VERSION ""

NS_ :

BS_:

BU_: VDM CMR_DSMC SOBDMC_HPCM_FD1 IPMA_ADAS PSCM ABS_ESC TCCM TCM_DSL PCM_HEV PCM ECM_Diesel GWM

BO_ 390 ACCDATA: 8 IPMA_ADAS
 SG_ AccBrkPulse_B_Rq : 36|1@0+ (1,0) [0|1] "SED"  ABS_ESC,GWM
 SG_ AccAutoResum_D_Rq : 7|2@0+ (1,0) [0|3] "SED"  PCM_HEV,PCM,ECM_Diesel
 SG_ AccBrkTot_A_Rq : 4|13@0+ (0.0039,-20) [-20|11.9449] "m/s^2"  GWM,ABS_ESC
 SG_ AccPrpl_A_Pred : 17|10@0+ (0.01,-5) [-5|5.23] "m/s^2"  GWM,ECM_Diesel,PCM,PCM_HEV
 SG_ AccVeh_V_Trg : 32|9@0+ (0.5,0) [0|255.5] "kph"  GWM,ECM_Diesel,PCM,PCM_HEV,TCM_DSL
 SG_ AccBrkPrkEl_B_Rq : 38|1@0+ (1,0) [0|1] "SED"  GWM,ABS_ESC
 SG_ Cmbb_B_Enbl : 50|1@0+ (1,0) [0|1] "SED"  GWM
 SG_ CmbbOvrrd_B_RqDrv : 51|1@0+ (1,0) [0|1] "SED"  GWM
 SG_ CmbbDeny_B_Actl : 37|1@0+ (1,0) [0|1] "SED"  GWM,ABS_ESC
 SG_ CmbbEngTqMn_B_Rq : 52|1@0+ (1,0) [0|1] "SED"  ECM_Diesel,PCM,PCM_HEV,GWM
 SG_ AccPrpl_A_Rq : 49|10@0+ (0.01,-5) [-5|5.23] "m/s^2"  GWM,ECM_Diesel,PCM,PCM_HEV
 SG_ AccDeny_B_Rq : 53|1@0+ (1,0) [0|1] "SED"  GWM,ECM_Diesel,PCM,PCM_HEV
 SG_ AccResumEnbl_B_Rq : 33|1@0+ (1,0) [0|1] "SED"  GWM,ECM_Diesel,PCM,PCM_HEV
 SG_ AccCancl_B_Rq : 39|1@0+ (1,0) [0|1] "SED"  GWM,ABS_ESC,ECM_Diesel,PCM,PCM_HEV
 SG_ AccBrkPrchg_B_Rq : 54|1@0+ (1,0) [0|1] "SED"  GWM,ABS_ESC
 SG_ AccBrkDecel_B_Rq : 55|1@0+ (1,0) [0|1] "SED"  GWM,ABS_ESC
 SG_ AccStopStat_B_Rq : 34|1@0+ (1,0) [0|1] "SED"  GWM,ECM_Diesel,PCM,PCM_HEV,ABS_ESC

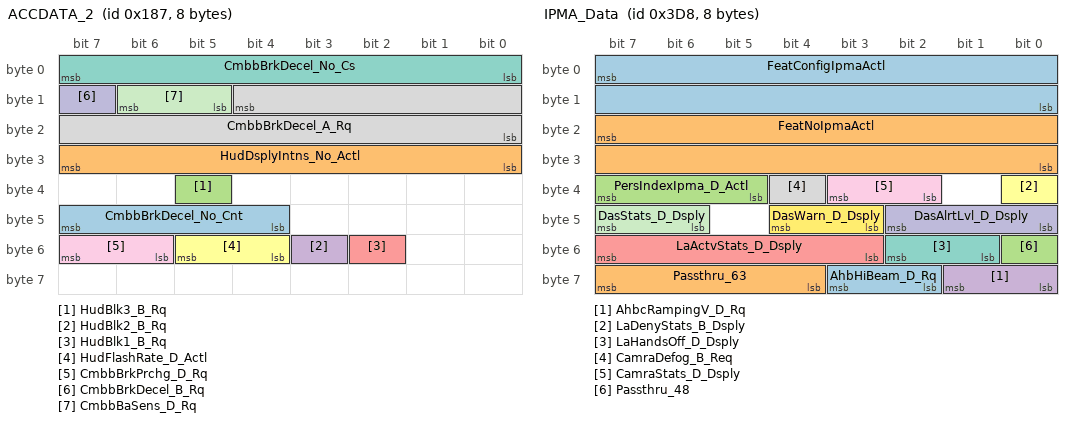
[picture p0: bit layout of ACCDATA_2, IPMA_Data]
BO_ 391 ACCDATA_2: 8 IPMA_ADAS
 SG_ CmbbBrkDecel_No_Cnt : 47|4@0+ (1,0) [0|15] "Unitless"  GWM,ABS_ESC
 SG_ HudDsplyIntns_No_Actl : 31|8@0+ (0.5,0) [0|100] "%"  GWM
 SG_ HudBlk3_B_Rq : 37|1@0+ (1,0) [0|1] "SED"  GWM
 SG_ HudBlk2_B_Rq : 51|1@0+ (1,0) [0|1] "SED"  GWM
 SG_ HudBlk1_B_Rq : 50|1@0+ (1,0) [0|1] "SED"  GWM
 SG_ HudFlashRate_D_Actl : 53|2@0+ (1,0) [0|3] "SED"  GWM
 SG_ CmbbBrkDecel_No_Cs : 7|8@0+ (1,0) [0|255] "Unitless"  GWM,ABS_ESC
 SG_ CmbbBrkDecel_A_Rq : 12|13@0+ (0.0039,-20) [-20|11.9449] "m/s^2"  ABS_ESC,GWM
 SG_ CmbbBrkPrchg_D_Rq : 55|2@0+ (1,0) [0|3] "SED"  ABS_ESC,GWM
 SG_ CmbbBrkDecel_B_Rq : 15|1@0+ (1,0) [0|1] "SED"  ABS_ESC,GWM
 SG_ CmbbBaSens_D_Rq : 14|2@0+ (1,0) [0|3] "SED"  ABS_ESC,GWM

BO_ 394 ACCDATA_3: 8 IPMA_ADAS
 SG_ HaDsply_No_Cs : 63|8@0+ (1,0) [0|255] "Unitless"  GWM
 SG_ HaDsply_No_Cnt : 4|4@0+ (1,0) [0|15] "Unitless"  GWM
 SG_ AccStopStat_D_Dsply : 41|2@0+ (1,0) [0|3] "SED"  GWM
 SG_ AccTrgDist2_D_Dsply : 27|4@0+ (1,0) [0|15] "SED"  GWM
 SG_ AccStopRes_B_Dsply : 54|1@0+ (1,0) [0|1] "SED"  GWM
 SG_ TjaWarn_D_Rq : 50|3@0+ (1,0) [0|7] "SED"  GWM
 SG_ Tja_D_Stat : 44|3@0+ (1,0) [0|7] "SED"  GWM
 SG_ TjaMsgTxt_D_Dsply : 53|3@0+ (1,0) [0|7] "SED"  GWM
 SG_ IaccLamp_D_Rq : 46|2@0+ (1,0) [0|3] "SED"  GWM
 SG_ AccMsgTxt_D2_Rq : 31|4@0+ (1,0) [0|15] "SED"  GWM
 SG_ FcwDeny_B_Dsply : 10|1@0+ (1,0) [0|1] "SED"  GWM
 SG_ FcwMemStat_B_Actl : 13|1@0+ (1,0) [0|1] "SED"  GWM
 SG_ AccTGap_B_Dsply : 35|1@0+ (1,0) [0|1] "SED"  GWM
 SG_ CadsAlignIncplt_B_Actl : 11|1@0+ (1,0) [0|1] "SED"  GWM
 SG_ AccFllwMde_B_Dsply : 17|1@0+ (1,0) [0|1] "SED"  GWM
 SG_ CadsRadrBlck_B_Actl : 22|1@0+ (1,0) [0|1] "SED"  GWM
 SG_ CmbbPostEvnt_B_Dsply : 15|1@0+ (1,0) [0|1] "SED"  GWM
 SG_ AccStopMde_B_Dsply : 0|1@0+ (1,0) [0|1] "SED"  GWM
 SG_ FcwMemSens_D_Actl : 20|2@0+ (1,0) [0|3] "SED"  GWM
 SG_ FcwMsgTxt_D_Rq : 7|3@0+ (1,0) [0|7] "SED"  GWM
 SG_ AccWarn_D_Dsply : 39|2@0+ (1,0) [0|3] "SED"  GWM
 SG_ FcwVisblWarn_B_Rq : 47|1@0+ (1,0) [0|1] "SED"  GWM
 SG_ FcwAudioWarn_B_Rq : 8|1@0+ (1,0) [0|1] "SED"  GWM
 SG_ AccTGap_D_Dsply : 34|3@0+ (1,0) [0|7] "SED"  GWM
 SG_ AccMemEnbl_B_RqDrv : 36|1@0+ (1,0) [0|1] "SED"  GWM
 SG_ FdaMem_B_Stat : 37|1@0+ (1,0) [0|1] "SED"  GWM

BO_ 984 IPMA_Data: 8 IPMA_ADAS
 SG_ FeatConfigIpmaActl : 7|16@0+ (1,0) [0|65535] "Undefined" GWM
 SG_ FeatNoIpmaActl : 23|16@0+ (1,0) [0|65535] "Number" GWM
 SG_ PersIndexIpma_D_Actl : 39|3@0+ (1,0) [0|7] "SED" GWM
 SG_ AhbcRampingV_D_Rq : 57|2@0+ (1,0) [0|3] "SED" GWM
 SG_ LaActvStats_D_Dsply : 55|5@0+ (1,0) [0|31] "SED" GWM
 SG_ LaDenyStats_B_Dsply : 32|1@0+ (1,0) [0|1] "SED" GWM
 SG_ LaHandsOff_D_Dsply : 50|2@0+ (1,0) [0|3] "SED" GWM
 SG_ CamraDefog_B_Req : 36|1@0+ (1,0) [0|1] "SED" GWM
 SG_ CamraStats_D_Dsply : 35|2@0+ (1,0) [0|3] "SED" GWM
 SG_ DasAlrtLvl_D_Dsply : 42|3@0+ (1,0) [0|7] "SED" GWM
 SG_ DasStats_D_Dsply : 47|2@0+ (1,0) [0|3] "SED" GWM
 SG_ DasWarn_D_Dsply : 44|2@0+ (1,0) [0|3] "SED" GWM
 SG_ AhbHiBeam_D_Rq : 59|2@0+ (1,0) [0|3] "SED" GWM
 SG_ Passthru_63 : 63|4@0+ (1,0) [0|15] "" XXX
 SG_ Passthru_48 : 48|1@0+ (1,0) [0|1] "" XXX

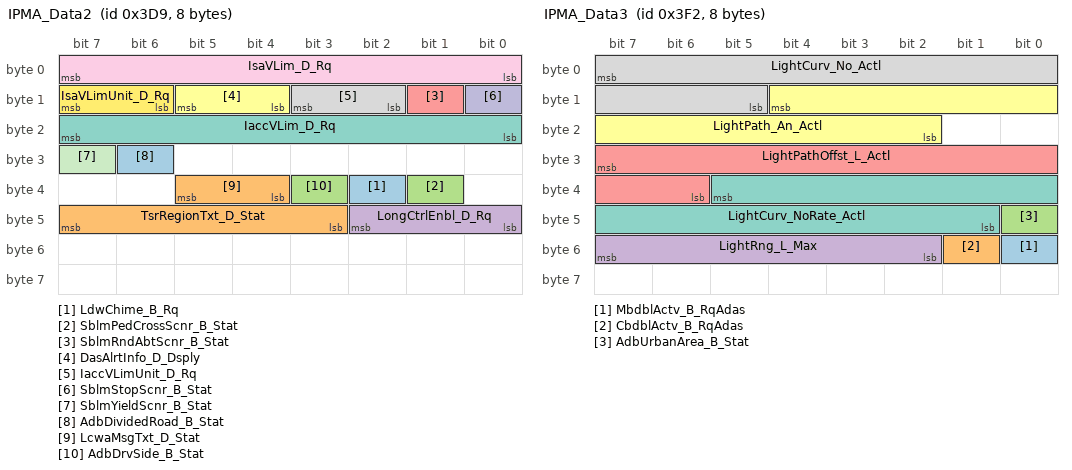
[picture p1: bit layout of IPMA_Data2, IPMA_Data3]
BO_ 985 IPMA_Data2: 8 IPMA_ADAS
 SG_ LdwChime_B_Rq : 34|1@0+ (1,0) [0|1] "SED" GWM
 SG_ TsrRegionTxt_D_Stat : 47|5@0+ (1,0) [0|31] "SED" GWM
 SG_ SblmPedCrossScnr_B_Stat : 33|1@0+ (1,0) [0|1] "SED" GWM
 SG_ LongCtrlEnbl_D_Rq : 42|3@0+ (1,0) [0|7] "SED" ECM_Diesel,PCM,PCM_HEV,GWM
 SG_ SblmRndAbtScnr_B_Stat : 9|1@0+ (1,0) [0|1] "SED" GWM
 SG_ DasAlrtInfo_D_Dsply : 13|2@0+ (1,0) [0|3] "SED" GWM
 SG_ IaccVLim_D_Rq : 23|8@0+ (1,0) [0|255] "SED" ECM_Diesel,GWM
 SG_ IaccVLimUnit_D_Rq : 11|2@0+ (1,0) [0|3] "SED" ECM_Diesel,GWM
 SG_ IsaVLim_D_Rq : 7|8@0+ (1,0) [0|255] "SED" ECM_Diesel,GWM
 SG_ SblmStopScnr_B_Stat : 8|1@0+ (1,0) [0|1] "SED" GWM
 SG_ SblmYieldScnr_B_Stat : 31|1@0+ (1,0) [0|1] "SED" GWM
 SG_ IsaVLimUnit_D_Rq : 15|2@0+ (1,0) [0|3] "SED" ECM_Diesel,GWM
 SG_ AdbDividedRoad_B_Stat : 30|1@0+ (1,0) [0|1] "SED" GWM
 SG_ LcwaMsgTxt_D_Stat : 37|2@0+ (1,0) [0|3] "SED" GWM
 SG_ AdbDrvSide_B_Stat : 35|1@0+ (1,0) [0|1] "SED" GWM

BO_ 1010 IPMA_Data3: 8 IPMA_ADAS
 SG_ MbdblActv_B_RqAdas : 48|1@0+ (1,0) [0|1] "SED"  GWM
 SG_ CbdblActv_B_RqAdas : 49|1@0+ (1,0) [0|1] "SED"  GWM
 SG_ AdbUrbanArea_B_Stat : 40|1@0+ (1,0) [0|1] "SED"  GWM
 SG_ LightRng_L_Max : 55|6@0+ (2,0) [0|126] "meter"  GWM
 SG_ LightPathOffst_L_Actl : 31|10@0+ (0.01,-5.12) [-5.12|5.11] "meter"  GWM
 SG_ LightPath_An_Actl : 12|11@0+ (0.0005,-0.5) [-0.5|0.5235] "radians"  GWM
 SG_ LightCurv_NoRate_Actl : 37|13@0+ (2.5E-007,-0.001024) [-0.001024|0.00102375] "1/meter"  GWM
 SG_ LightCurv_No_Actl : 7|11@0+ (2E-005,-0.02) [-0.02|0.02094] "1/meter"  GWM

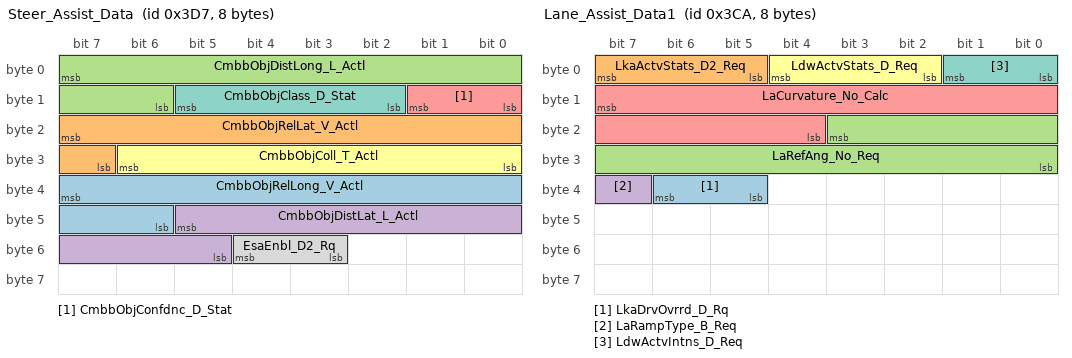
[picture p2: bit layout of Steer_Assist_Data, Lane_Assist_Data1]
BO_ 983 Steer_Assist_Data: 8 IPMA_ADAS
 SG_ CmbbObjRelLong_V_Actl : 39|10@0+ (0.1,-102.1) [-102.1|0] "meters/sec"  PSCM
 SG_ CmbbObjRelLat_V_Actl : 23|9@0+ (0.1,-25.5) [-25.5|25.4] "meters/sec"  PSCM
 SG_ CmbbObjDistLong_L_Actl : 7|10@0+ (0.1,0) [0|102.1] "meter"  PSCM
 SG_ CmbbObjDistLat_L_Actl : 45|9@0+ (0.1,-25.5) [-25.5|25.4] "meter"  PSCM
 SG_ CmbbObjConfdnc_D_Stat : 9|2@0+ (1,0) [0|3] "SED"  PSCM
 SG_ CmbbObjColl_T_Actl : 30|7@0+ (0.05,0) [0|6.25] "second"  PSCM
 SG_ CmbbObjClass_D_Stat : 13|4@0+ (1,0) [0|15] "SED"  PSCM
 SG_ EsaEnbl_D2_Rq : 52|2@0+ (1,0) [0|3] "SED"  PSCM

BO_ 970 Lane_Assist_Data1: 8 IPMA_ADAS
 SG_ LkaDrvOvrrd_D_Rq : 38|2@0+ (1,0) [0|3] "SED"  PSCM
 SG_ LkaActvStats_D2_Req : 7|3@0+ (1,0) [0|7] "SED"  PSCM
 SG_ LaRefAng_No_Req : 19|12@0+ (0.05,-102.4) [-102.4|102.3] "mrad"  PSCM
 SG_ LaRampType_B_Req : 39|1@0+ (1,0) [0|1] "SED"  PSCM
 SG_ LaCurvature_No_Calc : 15|12@0+ (5E-006,-0.01024) [-0.01024|0.01023] "1/m"  PSCM
 SG_ LdwActvStats_D_Req : 4|3@0+ (1,0) [0|7] "SED"  PSCM
 SG_ LdwActvIntns_D_Req : 1|2@0+ (1,0) [0|3] "SED"  PSCM

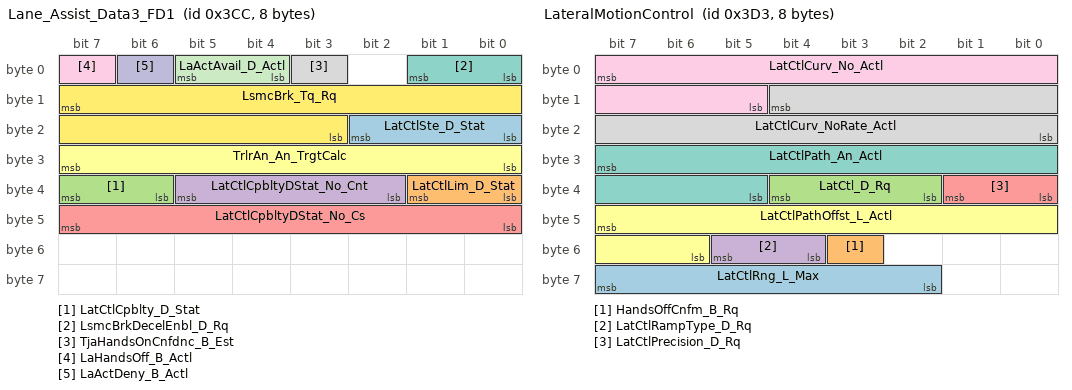
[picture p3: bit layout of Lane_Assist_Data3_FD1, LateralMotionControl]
BO_ 972 Lane_Assist_Data3_FD1: 8 PSCM
 SG_ LatCtlSte_D_Stat : 18|3@0+ (1,0) [0|7] "SED"  IPMA_ADAS,GWM
 SG_ LatCtlLim_D_Stat : 33|2@0+ (1,0) [0|3] "SED"  IPMA_ADAS,GWM
 SG_ LatCtlCpblty_D_Stat : 39|2@0+ (1,0) [0|3] "SED"  IPMA_ADAS,GWM
 SG_ LatCtlCpbltyDStat_No_Cnt : 37|4@0+ (1,0) [0|15] "Unitless"  IPMA_ADAS,GWM
 SG_ LatCtlCpbltyDStat_No_Cs : 47|8@0+ (1,0) [0|255] "Unitless"  IPMA_ADAS,GWM
 SG_ TrlrAn_An_TrgtCalc : 31|8@0+ (1,-128) [-128|127] "degrees"  IPMA_ADAS
 SG_ LsmcBrkDecelEnbl_D_Rq : 1|2@0+ (1,0) [0|3] "SED"  ABS_ESC
 SG_ TjaHandsOnCnfdnc_B_Est : 3|1@0+ (1,0) [0|1] "SED"  IPMA_ADAS
 SG_ LaHandsOff_B_Actl : 7|1@0+ (1,0) [0|1] "SED"  IPMA_ADAS,GWM
 SG_ LaActDeny_B_Actl : 6|1@0+ (1,0) [0|1] "SED"  IPMA_ADAS,GWM
 SG_ LaActAvail_D_Actl : 5|2@0+ (1,0) [0|3] "SED"  IPMA_ADAS,GWM
 SG_ LsmcBrk_Tq_Rq : 15|13@0+ (4,0) [0|32764] "Nm"  ABS_ESC

BO_ 979 LateralMotionControl: 8 IPMA_ADAS
 SG_ LatCtlRng_L_Max : 63|6@0+ (2,0) [0|126] "meter"  GWM
 SG_ HandsOffCnfm_B_Rq : 51|1@0+ (1,0) [0|1] "SED"  GWM
 SG_ LatCtl_D_Rq : 36|3@0+ (1,0) [0|7] "SED"  GWM
 SG_ LatCtlRampType_D_Rq : 53|2@0+ (1,0) [0|3] "SED"  GWM
 SG_ LatCtlPrecision_D_Rq : 33|2@0+ (1,0) [0|3] "SED"  GWM
 SG_ LatCtlPathOffst_L_Actl : 47|10@0+ (0.01,-5.12) [-5.12|5.11] "meter"  GWM
 SG_ LatCtlPath_An_Actl : 31|11@0+ (0.0005,-0.4995) [-0.4995|0.5240] "radians"  GWM
 SG_ LatCtlCurv_NoRate_Actl : 12|13@0+ (2.5E-007,-0.001024) [-0.001024|0.00102375] "1/meter"  GWM
 SG_ LatCtlCurv_No_Actl : 7|11@0+ (2E-005,-0.02) [-0.02|0.02094] "1/meter"  GWM

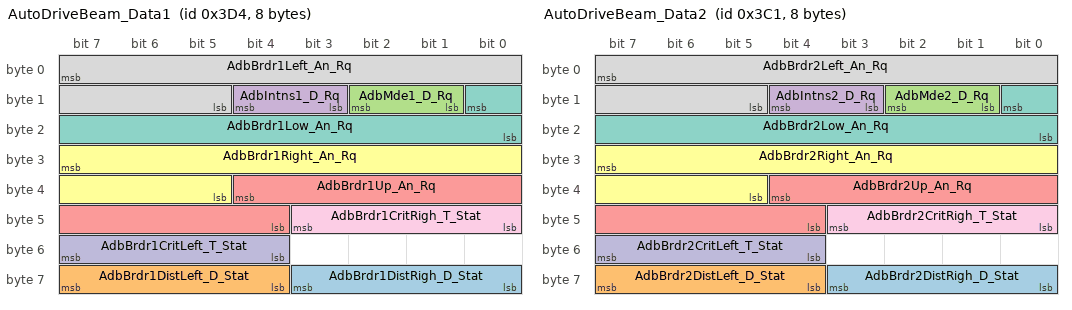
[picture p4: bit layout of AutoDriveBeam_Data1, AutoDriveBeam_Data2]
BO_ 980 AutoDriveBeam_Data1: 8 IPMA_ADAS
 SG_ AdbBrdr1DistRigh_D_Stat : 59|4@0+ (1,0) [0|15] "SED"  GWM
 SG_ AdbBrdr1DistLeft_D_Stat : 63|4@0+ (1,0) [0|15] "SED"  GWM
 SG_ AdbMde1_D_Rq : 10|2@0+ (1,0) [0|3] "SED"  GWM
 SG_ AdbIntns1_D_Rq : 12|2@0+ (1,0) [0|3] "SED"  GWM
 SG_ AdbBrdr1Up_An_Rq : 36|9@0+ (0.02,-8) [-8|2.18] "degrees"  GWM
 SG_ AdbBrdr1Right_An_Rq : 31|11@0+ (0.02,-20) [-20|20.9] "degrees"  GWM
 SG_ AdbBrdr1Low_An_Rq : 8|9@0+ (0.02,-8) [-8|2.18] "degrees"  GWM
 SG_ AdbBrdr1Left_An_Rq : 7|11@0+ (0.02,-20) [-20|20.9] "degrees"  GWM
 SG_ AdbBrdr1CritRigh_T_Stat : 43|4@0+ (100,0) [0|1500] "millisecond"  GWM
 SG_ AdbBrdr1CritLeft_T_Stat : 55|4@0+ (100,0) [0|1500] "millisecond"  GWM

BO_ 961 AutoDriveBeam_Data2: 8 IPMA_ADAS
 SG_ AdbBrdr2DistRigh_D_Stat : 59|4@0+ (1,0) [0|15] "SED"  GWM
 SG_ AdbBrdr2DistLeft_D_Stat : 63|4@0+ (1,0) [0|15] "SED"  GWM
 SG_ AdbMde2_D_Rq : 10|2@0+ (1,0) [0|3] "SED"  GWM
 SG_ AdbIntns2_D_Rq : 12|2@0+ (1,0) [0|3] "SED"  GWM
 SG_ AdbBrdr2Up_An_Rq : 36|9@0+ (0.02,-8) [-8|2.18] "degrees"  GWM
 SG_ AdbBrdr2Right_An_Rq : 31|11@0+ (0.02,-20) [-20|20.9] "degrees"  GWM
 SG_ AdbBrdr2Low_An_Rq : 8|9@0+ (0.02,-8) [-8|2.18] "degrees"  GWM
 SG_ AdbBrdr2Left_An_Rq : 7|11@0+ (0.02,-20) [-20|20.9] "degrees"  GWM
 SG_ AdbBrdr2CritRigh_T_Stat : 43|4@0+ (100,0) [0|1500] "millisecond"  GWM
 SG_ AdbBrdr2CritLeft_T_Stat : 55|4@0+ (100,0) [0|1500] "millisecond"  GWM

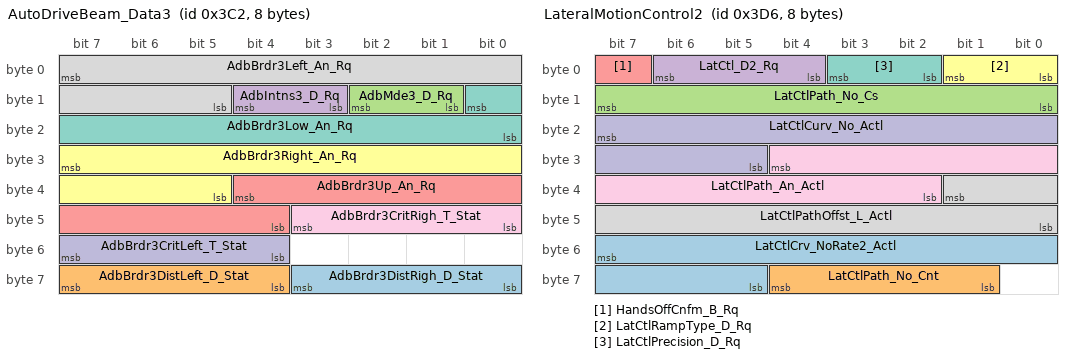
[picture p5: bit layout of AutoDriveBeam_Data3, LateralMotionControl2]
BO_ 962 AutoDriveBeam_Data3: 8 IPMA_ADAS
 SG_ AdbBrdr3DistRigh_D_Stat : 59|4@0+ (1,0) [0|15] "SED"  GWM
 SG_ AdbBrdr3DistLeft_D_Stat : 63|4@0+ (1,0) [0|15] "SED"  GWM
 SG_ AdbMde3_D_Rq : 10|2@0+ (1,0) [0|3] "SED"  GWM
 SG_ AdbIntns3_D_Rq : 12|2@0+ (1,0) [0|3] "SED"  GWM
 SG_ AdbBrdr3Up_An_Rq : 36|9@0+ (0.02,-8) [-8|2.18] "degrees"  GWM
 SG_ AdbBrdr3Right_An_Rq : 31|11@0+ (0.02,-20) [-20|20.9] "degrees"  GWM
 SG_ AdbBrdr3Low_An_Rq : 8|9@0+ (0.02,-8) [-8|2.18] "degrees"  GWM
 SG_ AdbBrdr3Left_An_Rq : 7|11@0+ (0.02,-20) [-20|20.9] "degrees"  GWM
 SG_ AdbBrdr3CritRigh_T_Stat : 43|4@0+ (100,0) [0|1500] "millisecond"  GWM
 SG_ AdbBrdr3CritLeft_T_Stat : 55|4@0+ (100,0) [0|1500] "millisecond"  GWM

BO_ 982 LateralMotionControl2: 8 IPMA_ADAS
 SG_ LatCtlCrv_NoRate2_Actl : 55|11@0+ (1E-006,-0.001024) [-0.001024|0.001023] "meter^2"  PSCM
 SG_ LatCtlPath_No_Cnt : 60|4@0+ (1,0) [0|15] "Unitless"  PSCM
 SG_ LatCtlPath_No_Cs : 15|8@0+ (1,0) [0|255] "Unitless"  PSCM
 SG_ LatCtl_D2_Rq : 6|3@0+ (1,0) [0|7] "SED"  PSCM
 SG_ HandsOffCnfm_B_Rq : 7|1@0+ (1,0) [0|1] "SED"  PSCM
 SG_ LatCtlRampType_D_Rq : 1|2@0+ (1,0) [0|3] "SED"  PSCM
 SG_ LatCtlPrecision_D_Rq : 3|2@0+ (1,0) [0|3] "SED"  PSCM
 SG_ LatCtlPathOffst_L_Actl : 33|10@0+ (0.01,-5.12) [-5.12|5.11] "meter"  PSCM
 SG_ LatCtlPath_An_Actl : 28|11@0+ (0.0005,-0.5) [-0.5|0.5235] "radians"  PSCM
 SG_ LatCtlCurv_No_Actl : 23|11@0+ (2E-005,-0.02) [-0.02|0.02094] "1/meter"  PSCM

CM_ BO_ 982 "not seen on Explorer, Escape or Focus. maybe for blue cruise?";

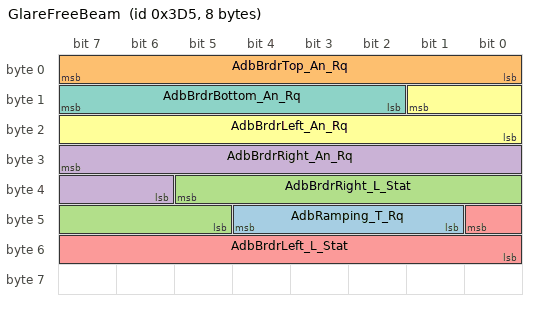
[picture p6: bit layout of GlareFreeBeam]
BO_ 981 GlareFreeBeam: 8 IPMA_ADAS
 SG_ AdbRamping_T_Rq : 44|4@0+ (200,0) [0|3000] "millisecond"  GWM
 SG_ AdbBrdrTop_An_Rq : 7|8@0+ (0.04,-9.54) [-9.54|0.58] "degrees"  GWM
 SG_ AdbBrdrRight_L_Stat : 37|9@0+ (2,0) [0|1018] "meter"  GWM
 SG_ AdbBrdrRight_An_Rq : 31|10@0+ (0.04,-20.4) [-20.4|20.44] "degrees"  GWM
 SG_ AdbBrdrLeft_L_Stat : 40|9@0+ (2,0) [0|1018] "meter"  GWM
 SG_ AdbBrdrLeft_An_Rq : 9|10@0+ (0.04,-20.4) [-20.4|20.44] "degrees"  GWM
 SG_ AdbBrdrBottom_An_Rq : 15|6@0+ (0.04,-1.86) [-1.86|0.58] "degrees"  GWM

CM_ BO_ 981 "not seen on Explorer";
